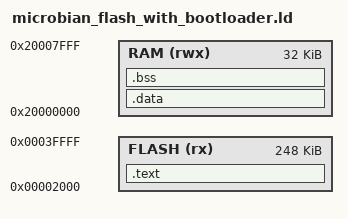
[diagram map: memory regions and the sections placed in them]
/* common/nRF51822.ld */
/* Copyright (c) 2018-20 J. M. Spivey */

/*MEMORY {
    FLASH (rx) : ORIGIN = 0x00000000, LENGTH = 256K
    RAM (rwx) :  ORIGIN = 0x20000000, LENGTH = 16K
}*/

MEMORY
{
  FLASH (rx) : ORIGIN = 0x00002000, LENGTH = 0x00040000-0x2000 /* First 8KB used by bootloader */
  RAM (rwx) : ORIGIN = 0x20000000, LENGTH = 0x00008000
}


OUTPUT_FORMAT ("elf32-littlearm")

/* Setting the entry address helps GDB to find the stack bottom */
ENTRY(__reset)

SECTIONS {
    .text : {
        KEEP(*(.vectors))
        *(.text*)
        *(.rodata*)
        . = ALIGN(4);
        __etext = .;
    } > FLASH

    .data : AT (LOADADDR(.text) + SIZEOF(.text)) {
        __data_start = .;
        *(.data*)
        . = ALIGN(4);
        __data_end = .;
    } > RAM

    .bss : {
        __bss_start = .;
        *(.bss*)
        *(COMMON)
        . = ALIGN(4);
        __bss_end = .;
        __end = .;
    } > RAM

    /* Set stack top to end of RAM, and move stack limit down by
       size of stack */
    __stack = ORIGIN(RAM) + LENGTH(RAM);
    __stack_limit = __stack - 2048;

    /* Check if data + stack exceeds RAM limit */
    ASSERT(__stack_limit >= __end, "region RAM overlaps with stack")
}
